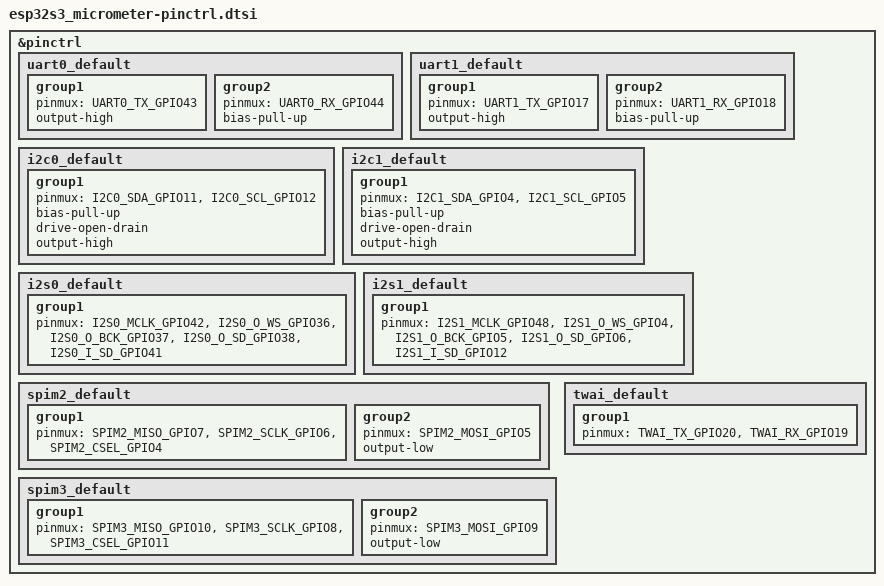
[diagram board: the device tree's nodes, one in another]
/*
 * Copyright (c) 2024 Espressif Systems (Shanghai) Co., Ltd.
 * Copyright (c) 2026 Auxspace e.V.
 *
 * SPDX-License-Identifier: Apache-2.0
 */

#include <zephyr/dt-bindings/pinctrl/esp-pinctrl-common.h>
#include <dt-bindings/pinctrl/esp32s3-pinctrl.h>
#include <zephyr/dt-bindings/pinctrl/esp32s3-gpio-sigmap.h>

&pinctrl {
	uart0_default: uart0_default {
		group1 {
			pinmux = <UART0_TX_GPIO43>;
			output-high;
		};

		group2 {
			pinmux = <UART0_RX_GPIO44>;
			bias-pull-up;
		};
	};

	uart1_default: uart1_default {
		group1 {
			pinmux = <UART1_TX_GPIO17>;
			output-high;
		};

		group2 {
			pinmux = <UART1_RX_GPIO18>;
			bias-pull-up;
		};
	};

	i2c0_default: i2c0_default {
		group1 {
			pinmux = <I2C0_SDA_GPIO11>,
				 <I2C0_SCL_GPIO12>;
			bias-pull-up;
			drive-open-drain;
			output-high;
		};
	};

	i2c1_default: i2c1_default {
		group1 {
			pinmux = <I2C1_SDA_GPIO4>,
				 <I2C1_SCL_GPIO5>;
			bias-pull-up;
			drive-open-drain;
			output-high;
		};
	};

	i2s0_default: i2s0_default {
		group1 {
			pinmux = <I2S0_MCLK_GPIO42>,
				 <I2S0_O_WS_GPIO36>,
				 <I2S0_O_BCK_GPIO37>,
				 <I2S0_O_SD_GPIO38>,
				 <I2S0_I_SD_GPIO41>;
		};
	};

	i2s1_default: i2s1_default {
		group1 {
			pinmux = <I2S1_MCLK_GPIO48>,
				 <I2S1_O_WS_GPIO4>,
				 <I2S1_O_BCK_GPIO5>,
				 <I2S1_O_SD_GPIO6>,
				 <I2S1_I_SD_GPIO12>;
		};
	};

	spim2_default: spim2_default {
		group1 {
			pinmux = <SPIM2_MISO_GPIO7>,
				 <SPIM2_SCLK_GPIO6>,
				 <SPIM2_CSEL_GPIO4>;
		};

		group2 {
			pinmux = <SPIM2_MOSI_GPIO5>;
			output-low;
		};
	};

	spim3_default: spim3_default {
		group1 {
			pinmux = <SPIM3_MISO_GPIO10>,
				 <SPIM3_SCLK_GPIO8>,
				 <SPIM3_CSEL_GPIO11>;
		};

		group2 {
			pinmux = <SPIM3_MOSI_GPIO9>;
			output-low;
		};
	};

	twai_default: twai_default {
		group1 {
			pinmux = <TWAI_TX_GPIO20>,
				 <TWAI_RX_GPIO19>;
		};
	};
};
